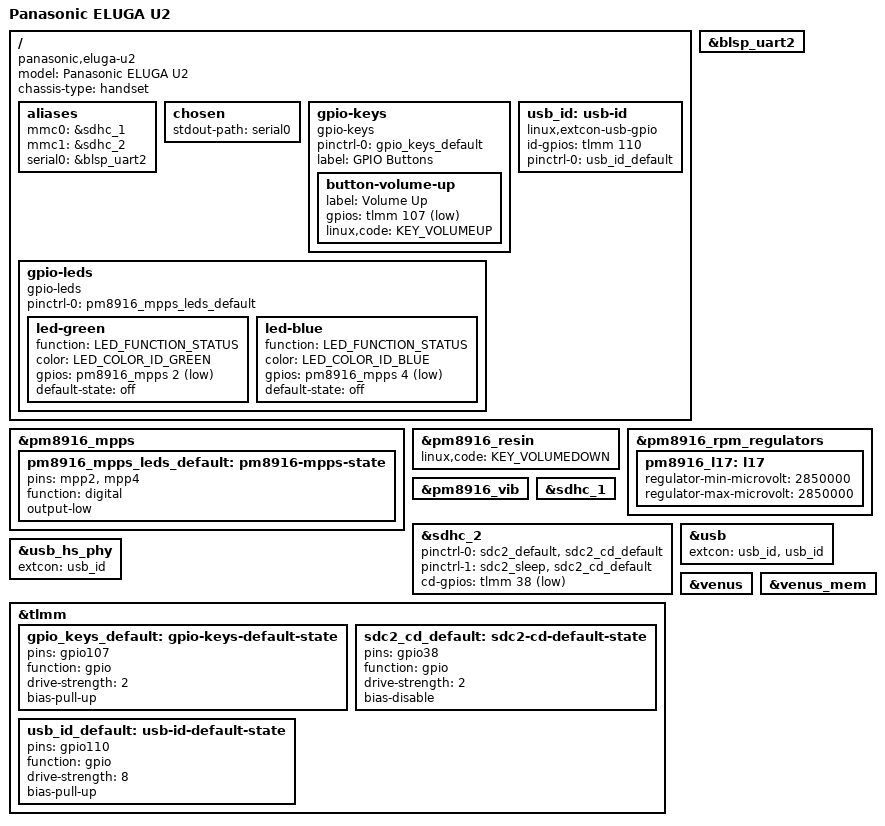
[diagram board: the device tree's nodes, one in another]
// SPDX-License-Identifier: GPL-2.0-only

/dts-v1/;

#include "msm8916-pm8916.dtsi"

#include <dt-bindings/gpio/gpio.h>
#include <dt-bindings/input/input.h>
#include <dt-bindings/leds/common.h>

/ {
	model = "Panasonic ELUGA U2";
	compatible = "panasonic,eluga-u2", "qcom,msm8916";
	chassis-type = "handset";

	aliases {
		mmc0 = &sdhc_1; /* eMMC */
		mmc1 = &sdhc_2; /* SD card */
		serial0 = &blsp_uart2;
	};

	chosen {
		stdout-path = "serial0";
	};

	gpio-keys {
		compatible = "gpio-keys";

		pinctrl-0 = <&gpio_keys_default>;
		pinctrl-names = "default";

		label = "GPIO Buttons";

		button-volume-up {
			label = "Volume Up";
			gpios = <&tlmm 107 GPIO_ACTIVE_LOW>;
			linux,code = <KEY_VOLUMEUP>;
		};
	};

	gpio-leds {
		compatible = "gpio-leds";
		pinctrl-0 = <&pm8916_mpps_leds_default>;
		pinctrl-names = "default";

		led-green {
			function = LED_FUNCTION_STATUS;
			color = <LED_COLOR_ID_GREEN>;
			gpios = <&pm8916_mpps 2 GPIO_ACTIVE_LOW>;
			default-state = "off";
		};

		led-blue {
			function = LED_FUNCTION_STATUS;
			color = <LED_COLOR_ID_BLUE>;
			gpios = <&pm8916_mpps 4 GPIO_ACTIVE_LOW>;
			default-state = "off";
		};
	};

	usb_id: usb-id {
		compatible = "linux,extcon-usb-gpio";
		id-gpios = <&tlmm 110 GPIO_ACTIVE_HIGH>;
		pinctrl-0 = <&usb_id_default>;
		pinctrl-names = "default";
	};
};

&blsp_uart2 {
	status = "okay";
};

&pm8916_mpps {
	pm8916_mpps_leds_default: pm8916-mpps-state {
		pins = "mpp2", "mpp4";
		function = "digital";
		output-low;
	};
};

&pm8916_resin {
	linux,code = <KEY_VOLUMEDOWN>;
	status = "okay";
};

&pm8916_rpm_regulators {
	pm8916_l17: l17 {
		regulator-min-microvolt = <2850000>;
		regulator-max-microvolt = <2850000>;
	};
};

&pm8916_vib {
	status = "okay";
};

&sdhc_1 {
	status = "okay";
};

&sdhc_2 {
	pinctrl-0 = <&sdc2_default &sdc2_cd_default>;
	pinctrl-1 = <&sdc2_sleep &sdc2_cd_default>;
	pinctrl-names = "default", "sleep";

	cd-gpios = <&tlmm 38 GPIO_ACTIVE_LOW>;

	status = "okay";
};

&usb {
	extcon = <&usb_id>, <&usb_id>;
	status = "okay";
};

&usb_hs_phy {
	extcon = <&usb_id>;
};

&tlmm {
	gpio_keys_default: gpio-keys-default-state {
		pins = "gpio107";
		function = "gpio";
		drive-strength = <2>;
		bias-pull-up;
	};

	sdc2_cd_default: sdc2-cd-default-state {
		pins = "gpio38";
		function = "gpio";
		drive-strength = <2>;
		bias-disable;
	};

	usb_id_default: usb-id-default-state {
		pins = "gpio110";
		function = "gpio";
		drive-strength = <8>;
		bias-pull-up;
	};
};

&venus {
	status = "okay";
};

&venus_mem {
	status = "okay";
};
